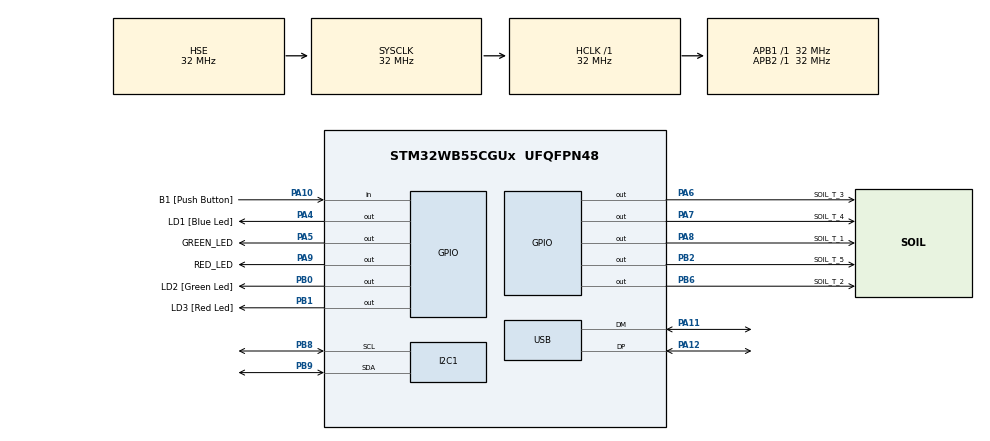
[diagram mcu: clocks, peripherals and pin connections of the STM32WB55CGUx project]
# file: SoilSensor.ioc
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Mcu.Family=STM32WB
RCC.CortexFreq_Value=32000000
PA14.GPIO_Label=JTCK
PA0.GPIO_Label=SOIL_M_1
PA11.Mode=Device
PB6.GPIO_Label=SOIL_T_2
PB0.GPIO_Label=LD2 [Green Led]
PA6.GPIO_Label=SOIL_T_3
PA5.PinState=GPIO_PIN_SET
RCC.SYSCLKSource=RCC_SYSCLKSOURCE_HSE
ProjectManager.StackSize=0x400
PA12.Signal=USB_DP
RCC.HCLKFreq_Value=32000000
RCC.APB2TimFreq_Value=32000000
PB6.Signal=GPIO_Output
OSC_OUT.Mode=HSE-External-Oscillator
OSC_OUT.Signal=RCC_OSC_OUT
RCC.AHBFreq_Value=32000000
RCC.HSE_VALUE=32000000
PB2.Signal=GPIO_Output
PC14-OSC32_IN.Mode=LSE-External-Oscillator
PA14.Mode=Serial_Wire
PB1.GPIO_Label=LD3 [Red Led]
PA10.GPIO_Label=B1 [Push Button]
SH.ADCx_IN8.0=ADC1_IN8
PA8.Signal=GPIO_Output
PA0.Signal=ADCx_IN5
RCC.APB3Freq_Value=16000000
NVIC.HSEM_IRQn=true\:0\:0\:false\:false\:true\:false\:true
Mcu.Package=UFQFPN48
PB9.Signal=I2C1_SDA
PB1.Signal=GPIO_Output
PA6.Signal=GPIO_Output
PA2.GPIO_Label=SOIL_M_3
PA10.Signal=GPIO_Input
VP_HSEM_VS_HSEM.Mode=HSEM_Activate
RCC.APB1TimFreq_Value=32000000
RCC.SMPSDivider=1
PA4.GPIO_Label=LD1 [Blue Led]
RCC.HSI48_VALUE=48000000
RCC.PLLSAI1N=24
PA3.Signal=ADCx_IN8
PB3.GPIO_Label=JTDO
PC15-OSC32_OUT.Mode=LSE-External-Oscillator
SH.ADCx_IN6.0=ADC1_IN6
PA9.GPIO_Label=RED_LED
PC14-OSC32_IN.Signal=RCC_OSC32_IN
PA13.Signal=SYS_JTMS-SWDIO
PA8.GPIO_Label=SOIL_T_1
ProjectManager.TargetToolchain=STM32CubeIDE
SH.ADCx_IN7.0=ADC1_IN7
PB9.Mode=I2C
PA9.Signal=GPIO_Output
I2C1.Timing=0x00707CBB
PA9.PinState=GPIO_PIN_SET
OSC_IN.Signal=RCC_OSC_IN
RCC.USBFreq_Value=48000000
PC15-OSC32_OUT.Signal=RCC_OSC32_OUT
PA1.Signal=ADCx_IN6
PA5.Signal=GPIO_Output
board=P-NUCLEO-WB55-USBDongle
RCC.VCOOutputFreq_Value=128000000
RCC.APB2Freq_Value=32000000
PA5.GPIO_ModeDefaultOutputPP=GPIO_MODE_OUTPUT_PP
RCC.ADCFreq_Value=48000000
PA1.GPIO_Label=SOIL_M_2
PA13.Mode=Serial_Wire
Mcu.Name=STM32WB55CGUx
VP_IPCC_VS_IPCC.Mode=IPCC_Activate
PA2.Signal=ADCx_IN7
PA13.GPIO_Label=JTMS
PA9.GPIO_ModeDefaultOutputPP=GPIO_MODE_OUTPUT_PP
PB3.Signal=SYS_JTDO-SWO
PA4.Signal=GPIO_Output
RCC.SYSCLKFreq_VALUE=32000000
PA7.GPIO_Label=SOIL_T_4
PA12.Mode=Device
PA5.GPIO_Label=GREEN_LED
OSC_IN.Mode=HSE-External-Oscillator
PA11.Signal=USB_DM
PA14.Signal=SYS_JTCK-SWCLK
PB2.GPIO_Label=SOIL_T_5
ProjectManager.HeapSize=0x200
RCC.HSI_VALUE=16000000
SH.ADCx_IN5.0=ADC1_IN5
NVIC.PriorityGroup=NVIC_PRIORITYGROUP_4
PB8.Mode=I2C
RCC.PLLN=32
PB8.Signal=I2C1_SCL
RCC.APB1Freq_Value=32000000
PB0.Signal=GPIO_Output
PA3.GPIO_Label=SOIL_M_4
PA7.Signal=GPIO_Output

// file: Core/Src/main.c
/* USER CODE BEGIN Header */
/**
  ******************************************************************************
  * @file           : main.c
  * @brief          : Main program body
  ******************************************************************************
  * @attention
  *
  * <h2><center>&copy; Copyright (c) 2021 STMicroelectronics.
  * All rights reserved.</center></h2>
  *
  * This software component is licensed by ST under BSD 3-Clause license,
  * the "License"; You may not use this file except in compliance with the
  * License. You may obtain a copy of the License at:
  *                        opensource.org/licenses/BSD-3-Clause
  *
  ******************************************************************************
  */
/* USER CODE END Header */
#include "main.h"
#include "i2c.h"
#include "ipcc.h"
#include "usb.h"
#include "gpio.h"

void SystemClock_Config(void);

int main(void)
{

  /* MCU Configuration--------------------------------------------------------*/

  /* Reset of all peripherals, Initializes the Flash interface and the Systick. */
  HAL_Init();

  /* Configure the system clock */
  SystemClock_Config();

  /* IPCC initialisation */
   MX_IPCC_Init();

  /* Initialize all configured peripherals */
  MX_GPIO_Init();
  MX_USB_PCD_Init();
  MX_I2C1_Init();

  /* Infinite loop */
  /* USER CODE BEGIN WHILE */
  while (1)
  {
	  HAL_GPIO_WritePin(GREEN_LED_GPIO_Port, GREEN_LED_Pin, GPIO_PIN_SET);
	  HAL_Delay(1000);
	  HAL_GPIO_WritePin(RED_LED_GPIO_Port, RED_LED_Pin, GPIO_PIN_SET);
	  HAL_Delay(1000);
	  HAL_GPIO_WritePin(GREEN_LED_GPIO_Port, GREEN_LED_Pin, GPIO_PIN_RESET);
	  HAL_Delay(1000);
	  HAL_GPIO_WritePin(RED_LED_GPIO_Port, RED_LED_Pin, GPIO_PIN_RESET);
	  HAL_Delay(1000);
	  HAL_GPIO_TogglePin(RED_LED_Pin, RED_LED_GPIO_Port);

	  HAL_GPIO_TogglePin(GREEN_LED_Pin, GREEN_LED_GPIO_Port);

    /* USER CODE END WHILE */

  }
}

void SystemClock_Config(void)
{
  RCC_OscInitTypeDef RCC_OscInitStruct = {0};
  RCC_ClkInitTypeDef RCC_ClkInitStruct = {0};
  RCC_PeriphCLKInitTypeDef PeriphClkInitStruct = {0};

  /** Macro to configure the PLL multiplication factor
  */
  __HAL_RCC_PLL_PLLM_CONFIG(RCC_PLLM_DIV1);
  /** Macro to configure the PLL clock source
  */
  __HAL_RCC_PLL_PLLSOURCE_CONFIG(RCC_PLLSOURCE_MSI);
  /** Configure LSE Drive Capability
  */
  HAL_PWR_EnableBkUpAccess();
  __HAL_RCC_LSEDRIVE_CONFIG(RCC_LSEDRIVE_LOW);
  /** Configure the main internal regulator output voltage
  */
  __HAL_PWR_VOLTAGESCALING_CONFIG(PWR_REGULATOR_VOLTAGE_SCALE1);
  /** Initializes the RCC Oscillators according to the specified parameters
  * in the RCC_OscInitTypeDef structure.
  */
  RCC_OscInitStruct.OscillatorType = RCC_OSCILLATORTYPE_HSI|RCC_OSCILLATORTYPE_HSE
                              |RCC_OSCILLATORTYPE_LSE|RCC_OSCILLATORTYPE_MSI;
  RCC_OscInitStruct.HSEState = RCC_HSE_ON;
  RCC_OscInitStruct.LSEState = RCC_LSE_ON;
  RCC_OscInitStruct.HSIState = RCC_HSI_ON;
  RCC_OscInitStruct.MSIState = RCC_MSI_ON;
  RCC_OscInitStruct.HSICalibrationValue = RCC_HSICALIBRATION_DEFAULT;
  RCC_OscInitStruct.MSICalibrationValue = RCC_MSICALIBRATION_DEFAULT;
  RCC_OscInitStruct.MSIClockRange = RCC_MSIRANGE_6;
  RCC_OscInitStruct.PLL.PLLState = RCC_PLL_NONE;
  if (HAL_RCC_OscConfig(&RCC_OscInitStruct) != HAL_OK)
  {
    Error_Handler();
  }
  /** Configure the SYSCLKSource, HCLK, PCLK1 and PCLK2 clocks dividers
  */
  RCC_ClkInitStruct.ClockType = RCC_CLOCKTYPE_HCLK4|RCC_CLOCKTYPE_HCLK2
                              |RCC_CLOCKTYPE_HCLK|RCC_CLOCKTYPE_SYSCLK
                              |RCC_CLOCKTYPE_PCLK1|RCC_CLOCKTYPE_PCLK2;
  RCC_ClkInitStruct.SYSCLKSource = RCC_SYSCLKSOURCE_HSE;
  RCC_ClkInitStruct.AHBCLKDivider = RCC_SYSCLK_DIV1;
  RCC_ClkInitStruct.APB1CLKDivider = RCC_HCLK_DIV1;
  RCC_ClkInitStruct.APB2CLKDivider = RCC_HCLK_DIV1;
  RCC_ClkInitStruct.AHBCLK2Divider = RCC_SYSCLK_DIV1;
  RCC_ClkInitStruct.AHBCLK4Divider = RCC_SYSCLK_DIV1;

  if (HAL_RCC_ClockConfig(&RCC_ClkInitStruct, FLASH_LATENCY_1) != HAL_OK)
  {
    Error_Handler();
  }
  /** Initializes the peripherals clocks
  */
  PeriphClkInitStruct.PeriphClockSelection = RCC_PERIPHCLK_SMPS|RCC_PERIPHCLK_I2C1
                              |RCC_PERIPHCLK_USB;
  PeriphClkInitStruct.PLLSAI1.PLLN = 24;
  PeriphClkInitStruct.PLLSAI1.PLLP = RCC_PLLP_DIV2;
  PeriphClkInitStruct.PLLSAI1.PLLQ = RCC_PLLQ_DIV2;
  PeriphClkInitStruct.PLLSAI1.PLLR = RCC_PLLR_DIV2;
  PeriphClkInitStruct.PLLSAI1.PLLSAI1ClockOut = RCC_PLLSAI1_USBCLK;
  PeriphClkInitStruct.I2c1ClockSelection = RCC_I2C1CLKSOURCE_PCLK1;
  PeriphClkInitStruct.UsbClockSelection = RCC_USBCLKSOURCE_PLLSAI1;
  PeriphClkInitStruct.SmpsClockSelection = RCC_SMPSCLKSOURCE_HSI;
  PeriphClkInitStruct.SmpsDivSelection = RCC_SMPSCLKDIV_RANGE0;
  if (HAL_RCCEx_PeriphCLKConfig(&PeriphClkInitStruct) != HAL_OK)
  {
    Error_Handler();
  }
  /** Enable MSI Auto calibration
  */
  HAL_RCCEx_EnableMSIPLLMode();
}

/* USER CODE BEGIN 4 */
//boolean DS18B20_Init()
//{
//  pinMode(DSPIN, OUTPUT);
//  digitalWrite(DSPIN, HIGH);
//  delayMicroseconds(5);
//  digitalWrite(DSPIN, LOW);
//  delayMicroseconds(750);//480-960
//  digitalWrite(DSPIN, HIGH);
//  pinMode(DSPIN, INPUT);
//  int t = 0;
//  while (digitalRead(DSPIN))
//  {
//    t++;
//    if (t > 60) return false;
//    delayMicroseconds(1);
//  }
//  t = 480 - t;
//  pinMode(DSPIN, OUTPUT);
//  delayMicroseconds(t);
//  digitalWrite(DSPIN, HIGH);
//  return true;
//}
//
//void DS18B20_Write(byte data)
//{
//  pinMode(DSPIN, OUTPUT);
//  for (int i = 0; i < 8; i++)
//  {
//    digitalWrite(DSPIN, LOW);
//    delayMicroseconds(10);
//    if (data & 1) digitalWrite(DSPIN, HIGH);
//    else digitalWrite(DSPIN, LOW);
//    data >>= 1;
//    delayMicroseconds(50);
//    digitalWrite(DSPIN, HIGH);
//  }
//}
//
//byte DS18B20_Read()
//{
//  pinMode(DSPIN, OUTPUT);
//  digitalWrite(DSPIN, HIGH);
//  delayMicroseconds(2);
//  byte data = 0;
//  for (int i = 0; i < 8; i++)
//  {
//    digitalWrite(DSPIN, LOW);
//    delayMicroseconds(1);
//    digitalWrite(DSPIN, HIGH);
//    pinMode(DSPIN, INPUT);
//    delayMicroseconds(5);
//    data >>= 1;
//    if (digitalRead(DSPIN)) data |= 0x80;
//    delayMicroseconds(55);
//    pinMode(DSPIN, OUTPUT);
//    digitalWrite(DSPIN, HIGH);
//  }
//  return data;
//}

/* USER CODE END 4 */

void Error_Handler(void)
{
  __disable_irq();
  while (1)
  {
  }
}

/************************ (C) COPYRIGHT STMicroelectronics *****END OF FILE****/
